VERSION ""

NS_ :

BS_:

BU_: IEB CCU PDC SCU TCU EMS
VAL_TABLE_ vtbSensorReqCause 15 "SNA" 2 "by Request 2" 1 "by Request 1" 0 "normal cycle" ;
VAL_TABLE_ vtbErrorDescription 255 "ERROR" ;

BO_ 2015 msg_broad_diag_request: 8 CCU
 SG_ sig_broad_diag_request : 0|64@1+ (1,0) [0|0] ""  EMS,IEB,PDC,SCU,TCU

BO_ 1867 msg_pdc_diag_response: 8 PDC
 SG_ sig_pdc_diag_response : 0|64@1+ (1,0) [0|0] ""  CCU

BO_ 1859 msg_pdc_diag_request: 8 CCU
 SG_ sig_pdc_diag_request : 0|64@1+ (1,0) [0|0] ""  PDC

BO_ 1866 msg_scu_diag_response: 8 SCU
 SG_ sig_scu_diag_response : 0|64@1+ (1,0) [0|0] ""  CCU

BO_ 1858 msg_scu_diag_request: 8 CCU
 SG_ sig_scu_diag_request : 0|64@1+ (1,0) [0|0] ""  SCU

BO_ 1865 msg_tcu_diag_response: 8 TCU
 SG_ sig_tcu_diag_response : 0|64@1+ (1,0) [0|0] ""  CCU

BO_ 1857 msg_tcu_diag_request: 8 CCU
 SG_ sig_tcu_diag_request : 0|64@1+ (1,0) [0|0] ""  TCU

BO_ 1864 msg_ems_diag_response: 8 EMS
 SG_ sig_ems_diag_response : 0|64@1+ (1,0) [0|0] ""  CCU

BO_ 1856 msg_ems_diag_request: 8 CCU
 SG_ sig_ems_diag_request : 0|64@1+ (1,0) [0|0] ""  EMS

BO_ 1061 msg_fconsole_cruise: 1 CCU
 SG_ sig_cruise_state : 0|1@1+ (1,0) [0|1] ""  EMS

BO_ 273 msg_ieb_brake: 1 IEB
 SG_ sig_ieb_brake : 0|1@1+ (1,0) [0|1] ""  EMS,TCU

BO_ 1058 msg_fconsole_drive: 1 CCU
 SG_ sig_console_drive_mode : 0|4@1+ (1,0) [0|15] ""  TCU,EMS

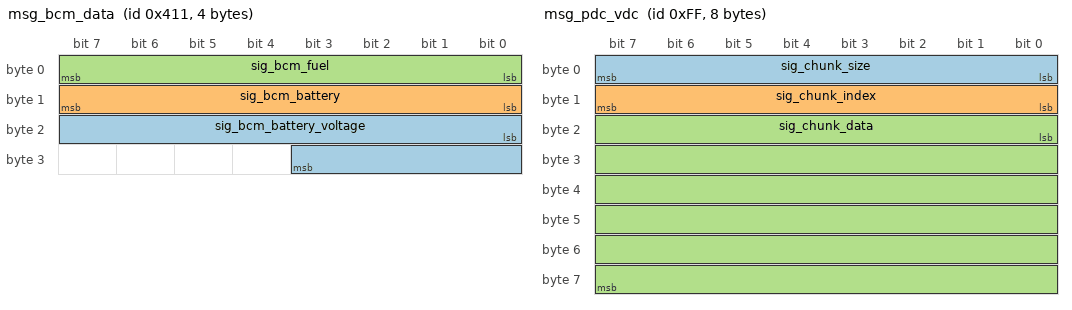
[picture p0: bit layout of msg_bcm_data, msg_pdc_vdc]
BO_ 1041 msg_bcm_data: 4 CCU
 SG_ sig_bcm_battery_voltage : 16|12@1+ (1,0) [0|4095] ""  TCU
 SG_ sig_bcm_battery : 8|8@1+ (1,0) [0|255] ""  TCU
 SG_ sig_bcm_fuel : 0|8@1+ (1,0) [0|255] ""  TCU

BO_ 255 msg_pdc_vdc: 8 PDC
 SG_ sig_chunk_size : 0|8@1+ (1,0) [0|255] ""  CCU
 SG_ sig_chunk_index : 8|8@1+ (1,0) [0|255] ""  CCU
 SG_ sig_chunk_data : 16|48@1+ (1,0) [0|281474976710655] ""  CCU

BO_ 79 msg_scu_alive: 1 SCU
 SG_ sig_scu_alive : 0|1@1+ (1,0) [0|1] ""  PDC

BO_ 78 msg_scu_pdc: 4 SCU
 SG_ sig_scu_dtc : 0|32@1+ (1,0) [0|4294967295] ""  PDC

BO_ 65 msg_ignition_info: 1 SCU
 SG_ sig_startbtn : 0|1@1+ (1,0) [0|1] ""  PDC

BO_ 47 msg_tcu_alive: 1 TCU
 SG_ sig_tcu_alive : 0|1@1+ (1,0) [0|1] ""  PDC

BO_ 46 msg_tcu_pdc: 4 TCU
 SG_ sig_tcu_dtc : 0|32@1+ (1,0) [0|4294967295] ""  PDC

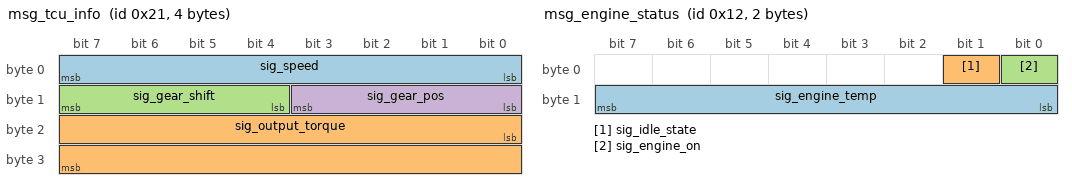
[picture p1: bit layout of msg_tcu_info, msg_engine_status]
BO_ 33 msg_tcu_info: 4 TCU
 SG_ sig_speed : 0|8@1+ (1,0) [0|255] "" Vector__XXX
 SG_ sig_output_torque : 16|16@1- (1,0) [-32768|32767] ""  PDC,CCU
 SG_ sig_gear_shift : 12|4@1+ (1,0) [0|15] ""  PDC,CCU
 SG_ sig_gear_pos : 8|4@1+ (1,0) [0|15] ""  PDC,CCU

BO_ 31 msg_ems_alive: 1 EMS
 SG_ sig_ems_alive : 0|1@1+ (1,0) [0|1] ""  PDC

BO_ 30 msg_ems_pdc: 4 EMS
 SG_ sig_ems_dtc : 0|32@1+ (1,0) [0|4294967295] ""  PDC

BO_ 18 msg_engine_status: 2 EMS
 SG_ sig_engine_temp : 8|8@1+ (1,0) [0|255] ""  TCU,PDC,CCU
 SG_ sig_idle_state : 1|1@1+ (1,0) [0|1] ""  PDC,CCU
 SG_ sig_engine_on : 0|1@1+ (1,0) [0|1] ""  PDC,TCU,CCU

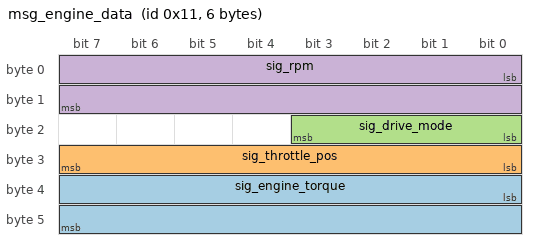
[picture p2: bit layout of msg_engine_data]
BO_ 17 msg_engine_data: 6 EMS
 SG_ sig_engine_torque : 32|16@1- (1,0) [-32768|32767] ""  PDC,TCU,CCU
 SG_ sig_throttle_pos : 24|8@1+ (1,0) [0|255] ""  PDC,TCU,CCU
 SG_ sig_drive_mode : 16|4@1+ (1,0) [0|15] ""  PDC,TCU,CCU
 SG_ sig_rpm : 0|16@1+ (1,0) [0|65535] ""  PDC,TCU,CCU

BA_DEF_  "DatabaseVersion" STRING ;
BA_DEF_  "Manufacturer" STRING ;
BA_DEF_ BU_  "NodeLayerModules" STRING ;
BA_DEF_  "BusType" STRING ;
BA_DEF_ SG_  "GenSigSendType" ENUM  "Cyclic","OnWrite","OnWriteWithRepetition","OnChange","OnChangeWithRepetition","IfActive","IfActiveWithRepetition","NoSigSendType","NotUsed","NotUsed","NotUsed","NotUsed","NotUsed";
BA_DEF_ BO_  "GenMsgSendType" ENUM  "Cyclic","NotUsed","NotUsed","NotUsed","NotUsed","Cyclic","NotUsed","IfActive","NoMsgSendType","NotUsed","vector_leerstring";
BA_DEF_ BO_  "GenMsgCycleTime" INT 0 50000;
BA_DEF_ BO_  "GenMsgCycleTimeFast" INT 0 50000;
BA_DEF_ BO_  "GenMsgILSupport" ENUM  "No","Yes";
BA_DEF_DEF_  "DatabaseVersion" "";
BA_DEF_DEF_  "Manufacturer" "Vector";
BA_DEF_DEF_  "NodeLayerModules" "CANoeILNLVector.dll";
BA_DEF_DEF_  "BusType" "CAN";
BA_DEF_DEF_  "GenSigSendType" "Cyclic";
BA_DEF_DEF_  "GenMsgSendType" "NoMsgSendType";
BA_DEF_DEF_  "GenMsgCycleTime" 200;
BA_DEF_DEF_  "GenMsgCycleTimeFast" 20;
BA_DEF_DEF_  "GenMsgILSupport" "Yes";
BA_ "DatabaseVersion" "1.1";
